# EVTULL register map
Vendor: Texas Instruments
Peripheral module from a debugger description file (folder CC23x0R2).
Registers are 32-bit, access per field, reset values left out (the file's numbers can be read two ways) unless marked. A register's access mark holds for its fields unless they carry their own. Offsets are as the file gives them; lines under a group give offsets from that group; [hi:lo] are bit positions; {n}, {i} and the like mark numbered series; 'fields as' and 'values as' point back to an identical list; <NAME> marks a mode.

## EVTULL — This is top module of ULL Event Fabric
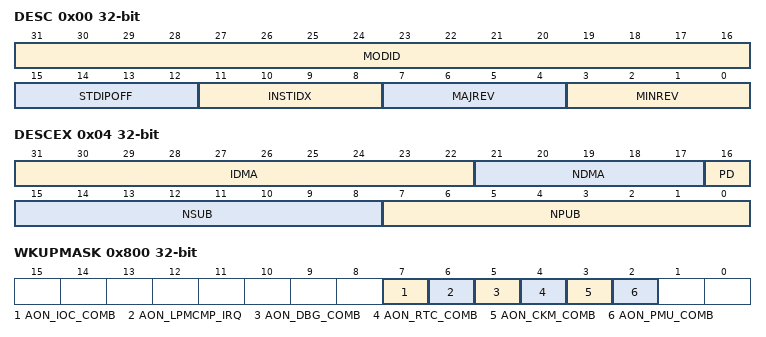
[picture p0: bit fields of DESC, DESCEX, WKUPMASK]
0x00 DESC ro — Description This register provides IP module ID, revision information, instance index and standard MMR registers offset.
  [31:16] MODID — Module identifier used to uniquely identify this IP.
  [15:12] STDIPOFF — Standard IP MMR block offset. Standard IP MMRs are the set of from aggregated IRQ registers till DTB. 0: Standard IP MMRs do not exist 0x1-0xF: Standard IP MMRs begin at offset of (64*STDIPOFF from the base IP address)
  [11:8] INSTIDX — IP Instance ID number. If multiple instances of IP exist in the device, this field can identify the instance number (0-15).
  [7:4] MAJREV — Major revision of IP (0-15).
  [3:0] MINREV — Minor revision of IP (0-15).
0x04 DESCEX ro — Extended Description This register provides configuration details of the IP to software drivers and end users.
  [31:22] IDMA — Number of DMA input channels
  [21:17] NDMA — Number of DMA output channels
  [16] PD — Power Domain. 0 : SVT 1 : ULL
  [15:8] NSUB — Number of Subscribers
  [7:0] NPUB — Number of Publishers
0x64 DTB — Digital test bus control register This register can be used to bring out IP internal signals to the pads for observation. 16 signals can be observed per select value.
  [0] SEL rw — Digital test bus selection mux control Non-zero select values output a 16 bit selected group of signals per value.
    0=DIS (All 16 observation signals are set to zero.)
0x400 NMISEL — Output Selection for CPU NMI Exception
  [5:0] PUBID rw — Read/write selection value. Writing any other value than values defined by a ENUM may result in undefined behavior.
    7=AON_IOC_COMB (IOC synchronous combined event, controlled by IOC:EVTCFG); 6=AON_LPMCMP_IRQ (AON LPCMP interrupt, controlled by SYS0:LPCMPCFG); 5=AON_DBG_COMB (DebugSS combined interrupt, interrupt flags can be found here DBGSS:MIS); 4=AON_RTC_COMB (AON_RTC event, controlled by the RTC:IMASK setting); 3=AON_CKM_COMB (CKMD combined interrupt request, interrupt flags can be found here CKMD:MIS); 2=AON_PMU_COMB (PMU combined interrupt request for BATMON, interrupt flags can be found here PMUD:EVENT); 0=NONE (Always inactive)
0x404 RTCCPTSEL — Output Selection for RTCCPT
  fields as NMISEL
0x800 WKUPMASK — WAKEUP Mask
  [7] AON_IOC_COMB rw — Wake-up mask for AON_IOC_COMB. 0 - Wakeup Disabled 1 - Wakeup Enabled
  [6] AON_LPMCMP_IRQ rw — Wake-up mask for AON_LPMCMP_IRQ. 0 - Wakeup Disabled 1 - Wakeup Enabled
  [5] AON_DBG_COMB rw — Wake-up mask for AON_DBG_COMB. 0 - Wakeup Disabled 1 - Wakeup Enabled
  [4] AON_RTC_COMB rw — Wake-up mask for AON_RTC_COMB. 0 - Wakeup Disabled 1 - Wakeup Enabled
  [3] AON_CKM_COMB rw — Wake-up mask for AON_CKM_COMB. 0 - Wakeup Disabled 1 - Wakeup Enabled
  [2] AON_PMU_COMB rw — Wake-up mask for AON_PMU_COMB. 0 - Wakeup Disabled 1 - Wakeup Enabled
